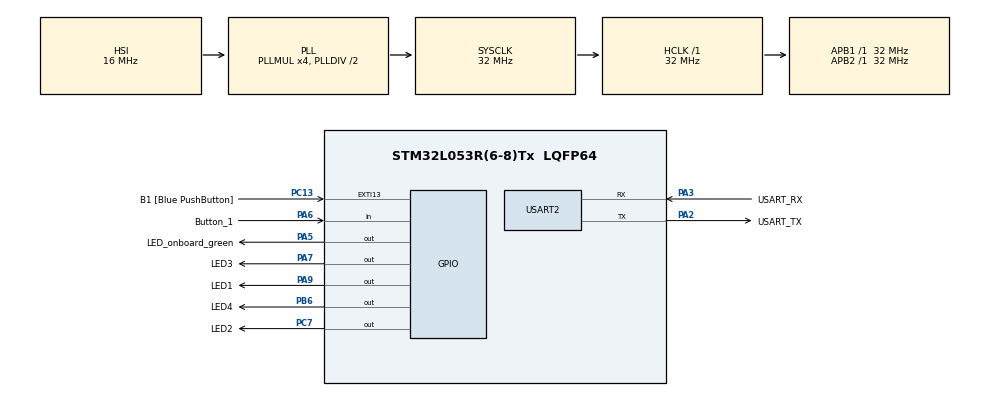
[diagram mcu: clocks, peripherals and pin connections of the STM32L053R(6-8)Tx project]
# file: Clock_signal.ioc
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Mcu.Family=STM32L0
Mcu.Name=STM32L053R(6-8)Tx
Mcu.Package=LQFP64
PA13.GPIO_Label=TMS
PA13.Mode=Serial_Wire
PA13.Signal=SYS_SWDIO
PA14.GPIO_Label=TCK
PA14.Mode=Serial_Wire
PA14.Signal=SYS_SWCLK
PA2.GPIO_Label=USART_TX
PA2.Mode=Asynchronous
PA2.Signal=USART2_TX
PA3.GPIO_Label=USART_RX
PA3.Mode=Asynchronous
PA3.Signal=USART2_RX
PA5.GPIO_Label=LED_onboard_green
PA5.Signal=GPIO_Output
PA6.GPIO_Label=Button_1
PA6.GPIO_PuPd=GPIO_PULLUP
PA6.Signal=GPIO_Input
PA7.GPIO_Label=LED3
PA7.PinState=GPIO_PIN_SET
PA7.Signal=GPIO_Output
PA9.GPIO_Label=LED1
PA9.PinState=GPIO_PIN_SET
PA9.Signal=GPIO_Output
PB6.GPIO_Label=LED4
PB6.PinState=GPIO_PIN_SET
PB6.Signal=GPIO_Output
PC13.GPIO_Label=B1 [Blue PushButton]
PC13.GPIO_ModeDefaultEXTI=GPIO_MODE_IT_FALLING
PC13.Signal=GPXTI13
PC14-OSC32_IN.Signal=RCC_OSC32_IN
PC15-OSC32_OUT.Signal=RCC_OSC32_OUT
PC7.GPIO_Label=LED2
PC7.PinState=GPIO_PIN_SET
PC7.Signal=GPIO_Output
PH0-OSC_IN.Signal=RCC_OSC_IN
PH1-OSC_OUT.Signal=RCC_OSC_OUT
ProjectManager.HeapSize=0x200
ProjectManager.StackSize=0x400
ProjectManager.TargetToolchain=TrueSTUDIO
RCC.AHBFreq_Value=32000000
RCC.APB1Freq_Value=32000000
RCC.APB1TimFreq_Value=32000000
RCC.APB2Freq_Value=32000000
RCC.APB2TimFreq_Value=32000000
RCC.HCLKFreq_Value=32000000
RCC.HSE_VALUE=8000000
RCC.HSI16_VALUE=16000000
RCC.HSI48_VALUE=48000000
RCC.HSI_VALUE=16000000
RCC.LSEState=RCC_LSE_ON
RCC.LSE_VALUE=32768
RCC.MSIClockRange=RCC_MSIRANGE_6
RCC.MSI_VALUE=4194000
RCC.PLLMUL=RCC_PLLMUL_4
RCC.SYSCLKFreq_VALUE=32000000
RCC.SYSCLKSource=RCC_SYSCLKSOURCE_PLLCLK
RCC.VCOOutputFreq_Value=64000000
TIM2.Period=999
TIM2.Prescaler=47999
USART2.VirtualMode-Asynchronous=VM_ASYNC
VP_TIM2_VS_ClockSourceINT.Mode=Internal
board=NUCLEO-L053R8

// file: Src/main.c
/* USER CODE BEGIN Header */
/**
  ******************************************************************************
  * @file           : main.c
  * @brief          : Main program body
  ******************************************************************************
  * @attention
  *
  * <h2><center>&copy; Copyright (c) 2019 STMicroelectronics.
  * All rights reserved.</center></h2>
  *
  * This software component is licensed by ST under BSD 3-Clause license,
  * the "License"; You may not use this file except in compliance with the
  * License. You may obtain a copy of the License at:
  *                        opensource.org/licenses/BSD-3-Clause
  *
  ******************************************************************************
  */
/* USER CODE END Header */

#include "main.h"

TIM_HandleTypeDef htim2;

UART_HandleTypeDef huart2;

void SystemClock_Config(void);
static void MX_GPIO_Init(void);
static void MX_USART2_UART_Init(void);
static void MX_TIM2_Init(void);

int main(void)
{

  /* MCU Configuration--------------------------------------------------------*/

  /* Reset of all peripherals, Initializes the Flash interface and the Systick. */
  HAL_Init();

  /* Configure the system clock */
  SystemClock_Config();

  /* Initialize all configured peripherals */
  MX_GPIO_Init();
  MX_USART2_UART_Init();
  MX_TIM2_Init();
  /* USER CODE BEGIN 2 */
HAL_TIM_Base_Start_IT(&htim2);

  /* USER CODE END 2 */

  /* Infinite loop */
  while (1)
  {

  }
}

void SystemClock_Config(void)
{
  RCC_OscInitTypeDef RCC_OscInitStruct = {0};
  RCC_ClkInitTypeDef RCC_ClkInitStruct = {0};
  RCC_PeriphCLKInitTypeDef PeriphClkInit = {0};

  /** Configure the main internal regulator output voltage
  */
  __HAL_PWR_VOLTAGESCALING_CONFIG(PWR_REGULATOR_VOLTAGE_SCALE1);
  /** Initializes the CPU, AHB and APB busses clocks
  */
  RCC_OscInitStruct.OscillatorType = RCC_OSCILLATORTYPE_HSI;
  RCC_OscInitStruct.HSIState = RCC_HSI_ON;
  RCC_OscInitStruct.HSICalibrationValue = RCC_HSICALIBRATION_DEFAULT;
  RCC_OscInitStruct.PLL.PLLState = RCC_PLL_ON;
  RCC_OscInitStruct.PLL.PLLSource = RCC_PLLSOURCE_HSI;
  RCC_OscInitStruct.PLL.PLLMUL = RCC_PLLMUL_4;
  RCC_OscInitStruct.PLL.PLLDIV = RCC_PLLDIV_2;
  if (HAL_RCC_OscConfig(&RCC_OscInitStruct) != HAL_OK)
  {
    Error_Handler();
  }
  /** Initializes the CPU, AHB and APB busses clocks
  */
  RCC_ClkInitStruct.ClockType = RCC_CLOCKTYPE_HCLK|RCC_CLOCKTYPE_SYSCLK
                              |RCC_CLOCKTYPE_PCLK1|RCC_CLOCKTYPE_PCLK2;
  RCC_ClkInitStruct.SYSCLKSource = RCC_SYSCLKSOURCE_PLLCLK;
  RCC_ClkInitStruct.AHBCLKDivider = RCC_SYSCLK_DIV1;
  RCC_ClkInitStruct.APB1CLKDivider = RCC_HCLK_DIV1;
  RCC_ClkInitStruct.APB2CLKDivider = RCC_HCLK_DIV1;

  if (HAL_RCC_ClockConfig(&RCC_ClkInitStruct, FLASH_LATENCY_1) != HAL_OK)
  {
    Error_Handler();
  }
  PeriphClkInit.PeriphClockSelection = RCC_PERIPHCLK_USART2;
  PeriphClkInit.Usart2ClockSelection = RCC_USART2CLKSOURCE_PCLK1;
  if (HAL_RCCEx_PeriphCLKConfig(&PeriphClkInit) != HAL_OK)
  {
    Error_Handler();
  }
}

static void MX_TIM2_Init(void)
{

  TIM_ClockConfigTypeDef sClockSourceConfig = {0};
  TIM_MasterConfigTypeDef sMasterConfig = {0};

  htim2.Instance = TIM2;
  htim2.Init.Prescaler = 47999;
  htim2.Init.CounterMode = TIM_COUNTERMODE_UP;
  htim2.Init.Period = 999;
  htim2.Init.ClockDivision = TIM_CLOCKDIVISION_DIV1;
  htim2.Init.AutoReloadPreload = TIM_AUTORELOAD_PRELOAD_DISABLE;
  if (HAL_TIM_Base_Init(&htim2) != HAL_OK)
  {
    Error_Handler();
  }
  sClockSourceConfig.ClockSource = TIM_CLOCKSOURCE_INTERNAL;
  if (HAL_TIM_ConfigClockSource(&htim2, &sClockSourceConfig) != HAL_OK)
  {
    Error_Handler();
  }
  sMasterConfig.MasterOutputTrigger = TIM_TRGO_RESET;
  sMasterConfig.MasterSlaveMode = TIM_MASTERSLAVEMODE_DISABLE;
  if (HAL_TIMEx_MasterConfigSynchronization(&htim2, &sMasterConfig) != HAL_OK)
  {
    Error_Handler();
  }

}

static void MX_USART2_UART_Init(void)
{

  huart2.Instance = USART2;
  huart2.Init.BaudRate = 115200;
  huart2.Init.WordLength = UART_WORDLENGTH_8B;
  huart2.Init.StopBits = UART_STOPBITS_1;
  huart2.Init.Parity = UART_PARITY_NONE;
  huart2.Init.Mode = UART_MODE_TX_RX;
  huart2.Init.HwFlowCtl = UART_HWCONTROL_NONE;
  huart2.Init.OverSampling = UART_OVERSAMPLING_16;
  huart2.Init.OneBitSampling = UART_ONE_BIT_SAMPLE_DISABLE;
  huart2.AdvancedInit.AdvFeatureInit = UART_ADVFEATURE_NO_INIT;
  if (HAL_UART_Init(&huart2) != HAL_OK)
  {
    Error_Handler();
  }

}

static void MX_GPIO_Init(void)
{
  GPIO_InitTypeDef GPIO_InitStruct = {0};

  /* GPIO Ports Clock Enable */
  __HAL_RCC_GPIOC_CLK_ENABLE();
  __HAL_RCC_GPIOH_CLK_ENABLE();
  __HAL_RCC_GPIOA_CLK_ENABLE();
  __HAL_RCC_GPIOB_CLK_ENABLE();

  /*Configure GPIO pin Output Level */
  HAL_GPIO_WritePin(LED_onboard_green_GPIO_Port, LED_onboard_green_Pin, GPIO_PIN_RESET);

  /*Configure GPIO pin Output Level */
  HAL_GPIO_WritePin(GPIOA, LED3_Pin|LED1_Pin, GPIO_PIN_SET);

  /*Configure GPIO pin Output Level */
  HAL_GPIO_WritePin(LED2_GPIO_Port, LED2_Pin, GPIO_PIN_SET);

  /*Configure GPIO pin Output Level */
  HAL_GPIO_WritePin(LED4_GPIO_Port, LED4_Pin, GPIO_PIN_SET);

  /*Configure GPIO pin : B1_Pin */
  GPIO_InitStruct.Pin = B1_Pin;
  GPIO_InitStruct.Mode = GPIO_MODE_IT_FALLING;
  GPIO_InitStruct.Pull = GPIO_NOPULL;
  HAL_GPIO_Init(B1_GPIO_Port, &GPIO_InitStruct);

  /*Configure GPIO pins : LED_onboard_green_Pin LED3_Pin LED1_Pin */
  GPIO_InitStruct.Pin = LED_onboard_green_Pin|LED3_Pin|LED1_Pin;
  GPIO_InitStruct.Mode = GPIO_MODE_OUTPUT_PP;
  GPIO_InitStruct.Pull = GPIO_NOPULL;
  GPIO_InitStruct.Speed = GPIO_SPEED_FREQ_LOW;
  HAL_GPIO_Init(GPIOA, &GPIO_InitStruct);

  /*Configure GPIO pin : Button_1_Pin */
  GPIO_InitStruct.Pin = Button_1_Pin;
  GPIO_InitStruct.Mode = GPIO_MODE_INPUT;
  GPIO_InitStruct.Pull = GPIO_PULLUP;
  HAL_GPIO_Init(Button_1_GPIO_Port, &GPIO_InitStruct);

  /*Configure GPIO pin : LED2_Pin */
  GPIO_InitStruct.Pin = LED2_Pin;
  GPIO_InitStruct.Mode = GPIO_MODE_OUTPUT_PP;
  GPIO_InitStruct.Pull = GPIO_NOPULL;
  GPIO_InitStruct.Speed = GPIO_SPEED_FREQ_LOW;
  HAL_GPIO_Init(LED2_GPIO_Port, &GPIO_InitStruct);

  /*Configure GPIO pin : LED4_Pin */
  GPIO_InitStruct.Pin = LED4_Pin;
  GPIO_InitStruct.Mode = GPIO_MODE_OUTPUT_PP;
  GPIO_InitStruct.Pull = GPIO_NOPULL;
  GPIO_InitStruct.Speed = GPIO_SPEED_FREQ_LOW;
  HAL_GPIO_Init(LED4_GPIO_Port, &GPIO_InitStruct);

}

/* USER CODE BEGIN 4 */
void HAL_TIM_PeriodElapsedCallback(TIM_HandleTypeDef *htim){
	if(htim ->Instance == TIM2) {
			HAL_GPIO_TogglePin(LED1_GPIO_Port, LED1_Pin); //Set Pin high/low
			HAL_GPIO_TogglePin(LED2_GPIO_Port, LED2_Pin); //Set Pin high/low
			  HAL_GPIO_TogglePin(LED3_GPIO_Port, LED3_Pin); //Set Pin high/low
			  HAL_GPIO_TogglePin(LED4_GPIO_Port, LED4_Pin); //Set Pin high/low

	}
/* USER CODE END 4 */

void Error_Handler(void)
{
}

/************************ (C) COPYRIGHT STMicroelectronics *****END OF FILE****/
